# srcc_reva_me14 register map
Registers are read-only, no defined reset value unless marked. A register's access mark holds for its fields unless they carry their own. Offsets are from the block's base; lines under a group give offsets from that group; [hi:lo] are bit positions; {n}, {i} and the like mark numbered series; 'fields as' and 'values as' point back to an identical list; <NAME> marks a mode.

## Memory map
0x40033000 SRCC size 0x1000 — External Memory Cache Controller Registers.

## SRCC — External Memory Cache Controller Registers.
Base 0x40033000
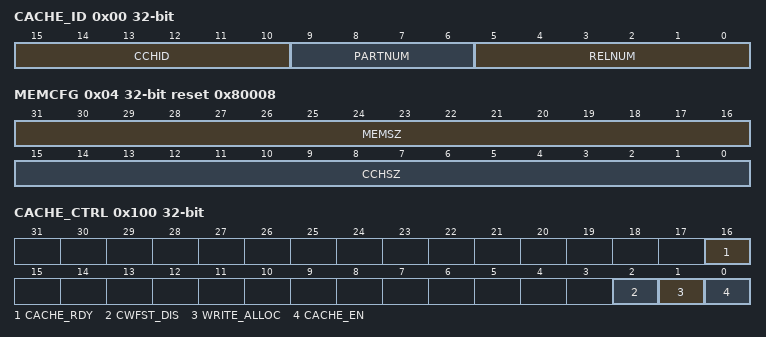
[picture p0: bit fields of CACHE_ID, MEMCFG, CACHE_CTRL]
0x00 CACHE_ID
  [15:10] CCHID — Cache ID. This field reflects the value of the C_ID_CACHEID configuration parameter.
  [9:6] PARTNUM — Part Number. This field reflects the value of C_ID_PART_NUMBER configuration parameter.
  [5:0] RELNUM — Release Number. Identifies the RTL release version.
0x04 MEMCFG reset 0x80008 — Memory Configuration Register.
  [31:16] MEMSZ — Main Memory Size. Indicates the total size, in units of 128 Kbytes, of code memory accessible to the cache controller.
  [15:0] CCHSZ — Cache Size. Indicates total size in Kbytes of cache.
0x100 CACHE_CTRL access not given — Cache Control and Status Register.
  [16] CACHE_RDY — Cache Ready flag. Cleared by hardware when at any time the cache as a whole is invalidated (including a system reset). When this bit is 0, the cache is effectively in bypass mode (instruction fetches will come from main memory or from the line fill buffer). Set by hardware when the invalidate operation is complete and the cache is ready.
    0=notReady; 1=ready
  [2] CWFST_DIS — Critical word first and streaming disable. This bit only writeable while the cache is disabled.
    1=dis (Critical word first and streaming disabled.); 0=en (Critical word first and streaming enabled.)
  [1] WRITE_ALLOC — Write Allocate Enable. This bit only writable while the cache is disabled.
    0=dis (Write-no-allocate.); 1=en (Write-allocate enabled.)
  [0] CACHE_EN — Cache Enable. Controls whether the cache is bypassed or is in use. Changing the state of this bit will cause the instruction cache to be flushed and its contents invalidated.
    0=dis (Cache Bypassed. Instruction data is stored in the line fill buffer but is not written to main cache memory array.); 1=en (Cache Enabled.)
0x700 INVALIDATE access not given — Invalidate All Cache Contents. Any time this register location is written (regardless of the data value), the cache controller immediately begins invalidating the entire contents of the cache memory. The cache will be in bypass mode until the invalidate operation is complete. System software can examine the Cache Ready bit (CACHE_CTRL.CACHE_RDY) to determine when the invalidate operation is complete. Note that it is not necessary to disable the cache controller prior to beginning this operation. Reads from this register always return 0.
  [31:0] IA — Invalidate all cache contents.
